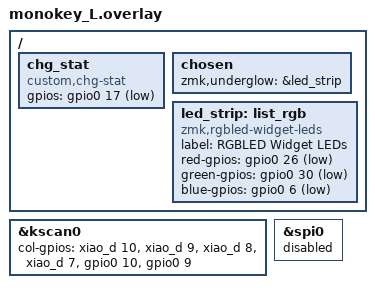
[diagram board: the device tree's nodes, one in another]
#include "monokey.dtsi"

&kscan0 {
        col-gpios
            = <&xiao_d 10 GPIO_ACTIVE_HIGH>
            , <&xiao_d 9 GPIO_ACTIVE_HIGH> 
            , <&xiao_d 8 GPIO_ACTIVE_HIGH> 
            , <&xiao_d 7 GPIO_ACTIVE_HIGH> 
            , <&gpio0 10 GPIO_ACTIVE_HIGH>
            , <&gpio0 9 GPIO_ACTIVE_HIGH>
            ;
};

/ {
    chg_stat: chg_stat {
        compatible = "custom,chg-stat";
        /* Xiao BLE の充電検知ピン P0.17 (Low = 充電中, High = 完了/未接続) */
        gpios = <&gpio0 17 GPIO_ACTIVE_LOW>;
        status = "okay";
    };

    chosen {
        zmk,underglow = &led_strip;
    };

    led_strip: list_rgb {
        compatible = "zmk,rgbled-widget-leds";
        label = "RGBLED Widget LEDs";

        /* XIAO BLEの物理3色LEDを直接叩く設定 */
        red-gpios   = <&gpio0 26 GPIO_ACTIVE_LOW>;
        green-gpios = <&gpio0 30 GPIO_ACTIVE_LOW>;
        blue-gpios  = <&gpio0 6  GPIO_ACTIVE_LOW>;
    };

};

&spi0 {
    status = "disabled";
};
